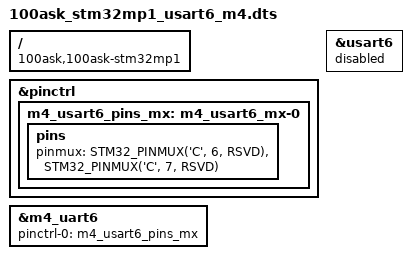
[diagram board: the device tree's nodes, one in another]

/*
 * Device tree overlay for usart6
 */

#include "dt-bindings/gpio/gpio.h"
#include "dt-bindings/pinctrl/stm32-pinfunc.h"

/dts-v1/;
/plugin/;

/ {
     compatible = "100ask,100ask-stm32mp1", "st,stm32mp157";
    fragment@0 {
        target = <&pinctrl>;
        __overlay__ {
			m4_usart6_pins_mx: m4_usart6_mx-0 {
				pins {
					pinmux = <STM32_PINMUX('C', 6, RSVD)>, /* USART6_TX */
							 <STM32_PINMUX('C', 7, RSVD)>; /* USART6_RX */
				};
			};
        };
    };
	
    fragment@1 {
        target = <&usart6>;
        __overlay__ {
			status = "disable";
        };
    };
	
		fragment@2 {
        target = <&m4_uart6>;
        __overlay__ {
			pinctrl-names = "default";
			pinctrl-0 = <&m4_usart6_pins_mx>;
			status = "okay";
        };
    };
};

